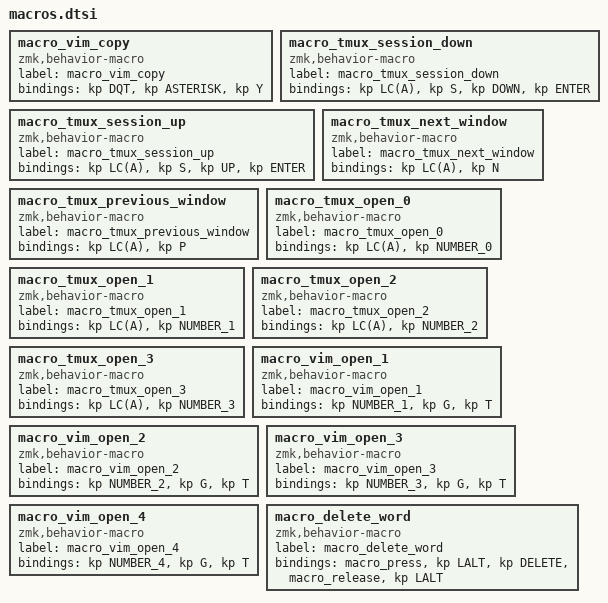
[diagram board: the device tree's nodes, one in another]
macro_vim_copy: macro_vim_copy{
compatible = "zmk,behavior-macro";
label = "macro_vim_copy";
#binding-cells = <0>;
bindings = <&kp DQT>, <&kp ASTERISK>, <&kp Y>;
};
macro_tmux_session_down: macro_tmux_session_down{
compatible = "zmk,behavior-macro";
label = "macro_tmux_session_down";
#binding-cells = <0>;
bindings = <&kp LC(A)>, <&kp S>, <&kp DOWN>, <&kp ENTER>;
};
macro_tmux_session_up: macro_tmux_session_up{
compatible = "zmk,behavior-macro";
label = "macro_tmux_session_up";
#binding-cells = <0>;
bindings = <&kp LC(A)>, <&kp S>, <&kp UP>, <&kp ENTER>;
};
macro_tmux_next_window: macro_tmux_next_window{
compatible = "zmk,behavior-macro";
label = "macro_tmux_next_window";
#binding-cells = <0>;
bindings = <&kp LC(A)>, <&kp N>;
};
macro_tmux_previous_window: macro_tmux_previous_window{
compatible = "zmk,behavior-macro";
label = "macro_tmux_previous_window";
#binding-cells = <0>;
bindings = <&kp LC(A)>, <&kp P>;
};
macro_tmux_open_0: macro_tmux_open_0{
compatible = "zmk,behavior-macro";
label = "macro_tmux_open_0";
#binding-cells = <0>;
bindings = <&kp LC(A)>, <&kp NUMBER_0>;
};
macro_tmux_open_1: macro_tmux_open_1{
compatible = "zmk,behavior-macro";
label = "macro_tmux_open_1";
#binding-cells = <0>;
bindings = <&kp LC(A)>, <&kp NUMBER_1>;
};
macro_tmux_open_2: macro_tmux_open_2{
compatible = "zmk,behavior-macro";
label = "macro_tmux_open_2";
#binding-cells = <0>;
bindings = <&kp LC(A)>, <&kp NUMBER_2>;
};
macro_tmux_open_3: macro_tmux_open_3{
compatible = "zmk,behavior-macro";
label = "macro_tmux_open_3";
#binding-cells = <0>;
bindings = <&kp LC(A)>, <&kp NUMBER_3>;
};

macro_vim_open_1: macro_vim_open_1{
compatible = "zmk,behavior-macro";
label = "macro_vim_open_1";
#binding-cells = <0>;
bindings = <&kp NUMBER_1>, <&kp G>, <&kp T>;
};
macro_vim_open_2: macro_vim_open_2{
compatible = "zmk,behavior-macro";
label = "macro_vim_open_2";
#binding-cells = <0>;
bindings = <&kp NUMBER_2>, <&kp G>, <&kp T>;
};
macro_vim_open_3: macro_vim_open_3{
compatible = "zmk,behavior-macro";
label = "macro_vim_open_3";
#binding-cells = <0>;
bindings = <&kp NUMBER_3>, <&kp G>, <&kp T>;
};
macro_vim_open_4: macro_vim_open_4{
compatible = "zmk,behavior-macro";
label = "macro_vim_open_4";
#binding-cells = <0>;
bindings = <&kp NUMBER_4>, <&kp G>, <&kp T>;
};

macro_delete_word: macro_delete_word{
compatible = "zmk,behavior-macro";
label = "macro_delete_word";
#binding-cells = <0>;
bindings
  = <&macro_press &kp LALT>
  , <&kp DELETE>
  , <&macro_release &kp LALT>
  ;
};
